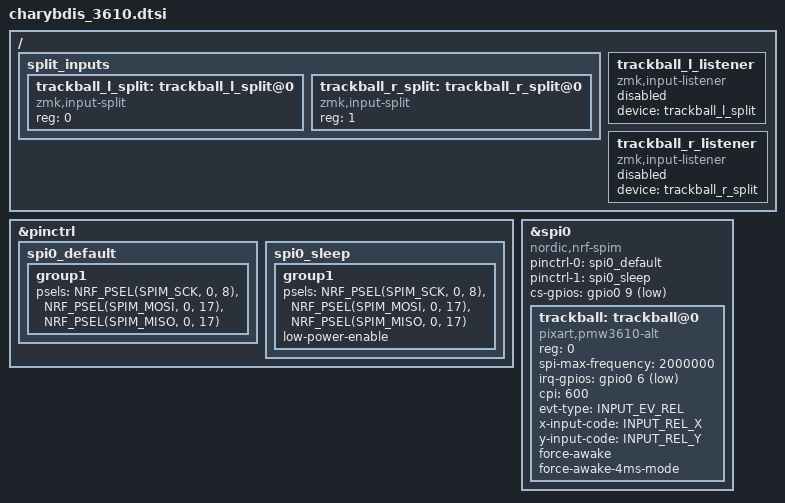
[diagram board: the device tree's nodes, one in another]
&pinctrl {
    spi0_default: spi0_default {
        group1 {
            psels = <NRF_PSEL(SPIM_SCK, 0, 8)>,
                <NRF_PSEL(SPIM_MOSI, 0, 17)>,
                <NRF_PSEL(SPIM_MISO, 0, 17)>;
        };
    };

    spi0_sleep: spi0_sleep {
        group1 {
            psels = <NRF_PSEL(SPIM_SCK, 0, 8)>,
                <NRF_PSEL(SPIM_MOSI, 0, 17)>,
                <NRF_PSEL(SPIM_MISO, 0, 17)>;
            low-power-enable;
        };
    };
};

#include <zephyr/dt-bindings/input/input-event-codes.h>

&spi0 {
    status = "okay";
    compatible = "nordic,nrf-spim";
    pinctrl-0 = <&spi0_default>;
    pinctrl-1 = <&spi0_sleep>;
    pinctrl-names = "default", "sleep";
    cs-gpios = <&gpio0 9 GPIO_ACTIVE_LOW>;

    trackball: trackball@0 {
        status = "okay";
        compatible = "pixart,pmw3610-alt";
        reg = <0>;
        spi-max-frequency = <2000000>;
        irq-gpios = <&gpio0 6 (GPIO_ACTIVE_LOW | GPIO_PULL_UP)>;
        cpi = <600>;
        evt-type = <INPUT_EV_REL>;
        x-input-code = <INPUT_REL_X>;
        y-input-code = <INPUT_REL_Y>;

        force-awake;
        /* keep the sensor awake while ZMK activity state is ACTIVE,
           fallback to normal downshift mode after ZMK goes into IDLE / SLEEP mode.
           thus, the sensor would be a `wakeup-source` */

        force-awake-4ms-mode;
        /* while force-awake is acitvated, enable this mode to force sampling per
           4ms, where the default sampling rate is 8ms. */
        /* NOTE: apply this mode if you need 250Hz with direct USB connection. */
    };
};

/ {
    split_inputs {
        #address-cells = <1>;
        #size-cells = <0>;

        trackball_l_split: trackball_l_split@0 {
            compatible = "zmk,input-split";
            reg = <0>;
        };

        trackball_r_split: trackball_r_split@0 {
            compatible = "zmk,input-split";
            reg = <1>;
        };
    };

    trackball_l_listener: trackball_l_listener {
        compatible = "zmk,input-listener";
        status = "disabled"; // overridden on central
        device = <&trackball_l_split>;
    };

    trackball_r_listener: trackball_r_listener {
        compatible = "zmk,input-listener";
        status = "disabled"; // overridden on central
        device = <&trackball_r_split>;
    };
};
